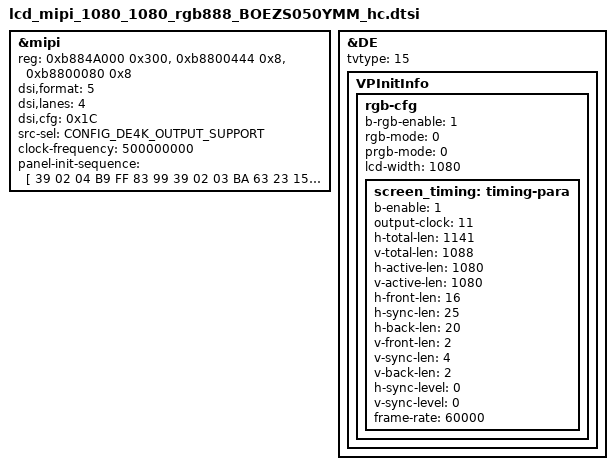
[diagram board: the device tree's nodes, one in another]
&mipi{
	reg = <0xb884A000 0x300>, <0xb8800444 0x8>,<0xb8800080 0x8>;

	/*
		* MIPI_COLOR_RGB565_0	=	0
		* MIPI_COLOR_RGB565_1	=	1
		* MIPI_COLOR_RGB565_2	=	2
		* MIPI_COLOR_RGB666_0	=	3
		* MIPI_COLOR_RGB666_1	=	4
		* MIPI_COLOR_RGB888	=	5
	*/
	dsi,format =<5>;

	dsi,lanes = <4>;

	/*
		* bit 6:5 MIPI_Virtual_Channel_Generic_ID
		* bit 4 :MIPI_CRC
		* bit 3 :MIPI_ECC
		* bit 2 :MIPI_Bus_Turn_request.
		* bit 1 :MIPI_EOTp
		* bit 0 :MIPI_EOTp
		*/
	dsi,cfg = <0x1C>;

	/*
		* 0: E_SRC_SEL_FXDE = 0
		* 1: E_SRC_SEL_4KDE
		* 2: E_SRC_SEL_HDMI_RX
		*/
	src-sel = <CONFIG_DE4K_OUTPUT_SUPPORT>;
	clock-frequency = <500000000>;
	// status = "okay";
};

&DE {
	tvtype = <15>;
	VPInitInfo {
		rgb-cfg{
			b-rgb-enable = <1>;
			/*
			 * 0: MODE_PRGB
			 * 1: MODE_SRGB
			 */
			rgb-mode = <0>;
			/*
			 * 0: MODE_PRGB_888_10bit 
			 * 1: MODE_PRGB_666
			 */
			prgb-mode = <0>; 
			lcd-width = <1080>;
			screen_timing: timing-para {
				/* bool type, 0 or 1*/
				b-enable = <1>;
				/*
				 * VPO_RGB_CLOCK_27M = 1,
				 * VPO_RGB_CLOCK_33M = 2,
				 * VPO_RGB_CLOCK_49M = 3,
				 * VPO_RGB_CLOCK_66M = 4,
				 * VPO_RGB_CLOCK_74M = 5,
				 * VPO_RGB_CLOCK_85M = 6,
				 * VPO_RGB_CLOCK_108M = 7,
				 * VPO_RGB_CLOCK_6_6M = 8,
				 * VPO_RGB_CLOCK_9M = 9,
				 * VPO_RGB_CLOCK_39_6M = 10,
				 * VPO_RGB_CLOCK_74_25M = 11,//H1600
				 * VPO_RGB_CLOCK_148_5M = 12,//H1600
				 * VPO_RGB_CLOCK_54M = 13,//H1600
				 * VPO_RGB_CLOCK_132M = 14,//H1600
				*/
				output-clock = <11>;

				h-total-len = <1141>;
				v-total-len = <1088>;

				h-active-len = <1080>;
				v-active-len = <1080>;

				h-front-len = <16>;
				h-sync-len = <25>;
				h-back-len = <20>;

				v-front-len = <2>;
				v-sync-len = <4>;
				v-back-len = <2>;
				/* bool type, 0 or 1*/
				h-sync-level = <0>;
				/* bool type, 0 or 1*/
				v-sync-level = <0>;
				frame-rate = <60000>;
			};
		};
	};
};
#if 0
&mipi{
panel-init-sequence = [
	15 78 02 11 00
	39 01 04 B9 FF 83 99
	39 01 03 BA 63 23
	15 01 02 D2 11
	39 01 0C B1 00 04 68 88 01 32 33 11 11 4D 57
	39 01 10 B2 00 80 80 45 05 07 BC 11 00 00 10 1F 70 03 C4
	39 01 2E B4 00 FF 02 A7 08 00 08 00 06 00 08 0A 00 30 05 0F 0A 65 03 03 00 14 FF 03 02 A7 08 00 08 00 06 00 08 0A 00 3B 05 0F 0A 03 00 14 FF 02 00
	39 01 22 D3 00 0C 03 03 00 00 14 04 32 10 09 00 09 32 10 00 00 00 00 00 00 00 00 11 00 02 02 13 00 00 00 0A 40
	39 01 21 D5 18 18 18 18 18 18 21 20 19 19 18 18 18 18 03 02 01 00 18 18 18 18 2F 2F 30 30 31 31 18 18 18 18
	39 01 21 D6 18 18 18 18 40 40 20 21 18 18 19 19 18 18 00 01 02 03 18 18 40 40 2F 2F 30 30 31 31 18 18 40 40
	39 01 11 D8 AA AE AA AA AA AE AA AA 00 00 00 00 00 00 00 00
	15 01 02 BD 01
	39 01 11 D8 FF FF FF FB FF FF FF FB 00 00 00 00 00 00 00 00
	15 01 02 BD 02
	39 01 09 D8 FF FF FF FB FF FF FF FB
	15 01 02 BD 00
	39 01 03 C7 00 88
	39 01 03 C6 FF F9
	39 01 37 E0 08 23 27 22 4A 51 5D 58 61 6C 74 7B 7F 88 8F 92 97 A0 A2 AA 9E AC B1 5C 58 65 73 08 23 27 22 4A 51 5D 58 61 6C 74 7B 7F 88 8F 92 97 A0 A2 AA 9E AC B1 5C 58 65 73
	15 01 02 CC 04
	15 01 02 CB 0A
	39 01 05 CF 00 14 00 80
	05 01 01 05
	15 64 02 29 00
	];
};
#endif
#if 1
&mipi{
panel-init-sequence = [
	39 02 04 B9 FF 83 99 
	39 02 03 BA 63 23 
	15 02 02 D2 11 
	39 02 0C B1 00 04 68 88 01 32 33 11 11 4D 57
	39 00 10 B2 00 80 80 45 05 07 BC 11 00 00 10 1F 70 03 C4 
	39 00 2E B4 00 FF 02 A7 08 00 08 00 06 00 08 0A 00 30 05 0F 0A 65 03 03 00 14 FF 03 02 A7 08 00 08 00 06 00 08 0A 00 3B 05 0F 0A 03 00 14 FF 02 00 
	39 00 22 D3 00 0C 03 03 00 00 14 04 32 10 09 00 09 32 10 00 00 00 00 00 00 00 00 11 00 02 02 13 00 00 00 0A 40 
	39 00 21 D5 18 18 18 18 18 18 21 20 19 19 18 18 18 18 03 02 01 00 18 18 18 18 2F 2F 30 30 31 31 18 18 18 18 
	39 00 21 D6 18 18 18 18 40 40 20 21 18 18 19 19 18 18 00 01 02 03 18 18 40 40 2F 2F 30 30 31 31 18 18 40 40 
	39 00 11 D8 AA AE AA AA AA AE AA AA 00 00 00 00 00 00 00 00 
	15 01 02 BD 01 
	39 00 11 D8 FF FF FF FB FF FF FF FB 00 00 00 00 00 00 00 00 
	15 01 02 BD 02
	39 00 09 D8 FF FF FF FB FF FF FF FB
	15 01 02 BD 00 
	39 00 03 C7 00 88 
	39 00 03 C6 FF F9 
	39 00 37 E0 08 23 27 22 4A 51 5D 58 61 6C 74 7B 7F 88 8F 92 97 A0 A2 AA 9E AC B1 5C 58 65 73 08 23 27 22 4A 51 5D 58 61 6C 74 7B 7F 88 8F 92 97 A0 A2 AA 9E AC B1 5C 58 65 73 
	15 01 02 CC 04 
	15 01 02 CB 0A 
	39 00 04 CF 00 14 00 
	05 78 01 11 
	05 64 01 29 
	39 02 04 B9 FF 83 99 
	39 02 03 BA 63 23 
	15 02 02 D2 11 
	39 02 0C B1 00 04 68 88 01 32 33 11 11 4D 57
	39 00 10 B2 00 80 80 45 05 07 BC 11 00 00 10 1F 70 03 C4  
	39 00 2E B4 00 FF 02 A7 08 00 08 00 06 00 08 0A 00 30 05 0F 0A 65 03 03 00 14 FF 03 02 A7 08 00 08 00 06 00 08 0A 00 3B 05 0F 0A 03 00 14 FF 02 00 
	39 00 22 D3 00 0C 03 03 00 00 14 04 32 10 09 00 09 32 10 00 00 00 00 00 00 00 00 11 00 02 02 13 00 00 00 0A 40 
	39 00 21 D5 18 18 18 18 18 18 21 20 19 19 18 18 18 18 03 02 01 00 18 18 18 18 2F 2F 30 30 31 31 18 18 18 18 
	39 00 21 D6 18 18 18 18 40 40 20 21 18 18 19 19 18 18 00 01 02 03 18 18 40 40 2F 2F 30 30 31 31 18 18 40 40 
	39 00 11 D8 AA AE AA AA AA AE AA AA 00 00 00 00 00 00 00 00 
	15 01 02 BD 01 
	39 00 11 D8 FF FF FF FB FF FF FF FB 00 00 00 00 00 00 00 00 
	15 01 02 BD 02
	39 00 09 D8 FF FF FF FB FF FF FF FB
	15 01 02 BD 00 
	39 00 03 C7 00 88 
	39 00 03 C6 FF F9 
	39 00 37 E0 08 23 27 22 4A 51 5D 58 61 6C 74 7B 7F 88 8F 92 97 A0 A2 AA 9E AC B1 5C 58 65 73 08 23 27 22 4A 51 5D 58 61 6C 74 7B 7F 88 8F 92 97 A0 A2 AA 9E AC B1 5C 58 65 73 
	15 01 02 CC 04 
	15 01 02 CB 0A 
	39 00 04 CF 00 14 00 
	05 01 01 21
	05 78 01 11 
	05 64 01 29 
	];
};
#endif
